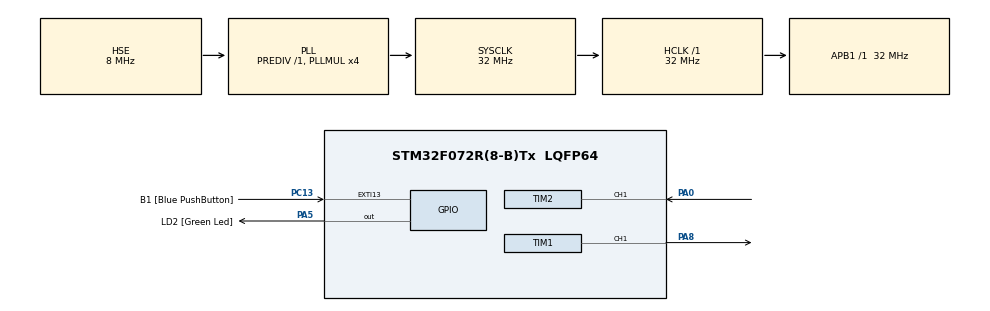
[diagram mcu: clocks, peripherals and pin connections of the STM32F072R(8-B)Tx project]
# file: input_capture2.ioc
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Mcu.Family=STM32F0
Mcu.Name=STM32F072R(8-B)Tx
Mcu.Package=LQFP64
NVIC.TIM2_IRQn=true\:0\:0\:false\:false\:true\:true\:true\:true
PA0.Signal=S_TIM2_CH1_ETR
PA13.GPIO_Label=TMS
PA13.Signal=SYS_SWDIO
PA14.GPIO_Label=TCK
PA14.Signal=SYS_SWCLK
PA2.GPIO_Label=USART_TX
PA2.GPIO_Mode=GPIO_MODE_AF_PP
PA2.GPIO_PuPd=GPIO_NOPULL
PA2.GPIO_Speed=GPIO_SPEED_FREQ_LOW
PA2.Signal=USART2_TX
PA3.GPIO_Label=USART_RX
PA3.GPIO_Mode=GPIO_MODE_AF_PP
PA3.GPIO_PuPd=GPIO_NOPULL
PA3.GPIO_Speed=GPIO_SPEED_FREQ_LOW
PA3.Signal=USART2_RX
PA5.GPIO_Label=LD2 [Green Led]
PA5.GPIO_Mode=GPIO_MODE_OUTPUT_PP
PA5.GPIO_PuPd=GPIO_NOPULL
PA5.GPIO_Speed=GPIO_SPEED_FREQ_LOW
PA5.Signal=GPIO_Output
PA8.Signal=S_TIM1_CH1
PC13.GPIO_Label=B1 [Blue PushButton]
PC13.GPIO_ModeDefaultEXTI=GPIO_MODE_IT_FALLING
PC13.Signal=GPXTI13
PC14-OSC32_IN.Signal=RCC_OSC32_IN
PC15-OSC32_OUT.Signal=RCC_OSC32_OUT
PF0-OSC_IN.Mode=HSE-External-Oscillator
PF0-OSC_IN.Signal=RCC_OSC_IN
PF1-OSC_OUT.Mode=HSE-External-Oscillator
PF1-OSC_OUT.Signal=RCC_OSC_OUT
ProjectManager.HeapSize=0x200
ProjectManager.StackSize=0x400
ProjectManager.TargetToolchain=STM32CubeIDE
RCC.AHBFreq_Value=32000000
RCC.APB1Freq_Value=32000000
RCC.APB1TimFreq_Value=32000000
RCC.FLatency-AdvancedSettings=FLASH_LATENCY_1
RCC.HCLKFreq_Value=32000000
RCC.PLLMUL=RCC_PLL_MUL4
RCC.PLLSourceVirtual=RCC_PLLSOURCE_HSE
RCC.SYSCLKFreq_VALUE=32000000
RCC.SYSCLKSource=RCC_SYSCLKSOURCE_PLLCLK
SH.S_TIM1_CH1.0=TIM1_CH1,PWM Generation1 CH1
SH.S_TIM2_CH1_ETR.0=TIM2_CH1,PWM_Input_1
TIM1.Channel-PWM\ Generation1\ CH1=TIM_CHANNEL_1
TIM1.Period=200-1
TIM1.Prescaler=32-1
TIM1.Pulse-PWM\ Generation1\ CH1=99
TIM2.Prescaler=32-1
VP_TIM1_VS_ClockSourceINT.Mode=Internal
VP_TIM2_VS_ClockSourceINT.Mode=Internal
board=NUCLEO-F072RB

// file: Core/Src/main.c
/* USER CODE BEGIN Header */
/**
  ******************************************************************************
  * @file           : main.c
  * @brief          : Main program body
  ******************************************************************************
  * @attention
  *
  * Copyright (c) 2022 STMicroelectronics.
  * All rights reserved.
  *
  * This software is licensed under terms that can be found in the LICENSE file
  * in the root directory of this software component.
  * If no LICENSE file comes with this software, it is provided AS-IS.
  *
  ******************************************************************************
  */
/* USER CODE END Header */
#include "main.h"

 TIM_HandleTypeDef htim1;
TIM_HandleTypeDef htim2;

void SystemClock_Config(void);
static void MX_GPIO_Init(void);
static void MX_TIM1_Init(void);
static void MX_TIM2_Init(void);

/* USER CODE BEGIN 0 */
uint32_t Icval = 0;
uint32_t freq = 0;
float duty = 0;

void HAL_TIM_IC_CaptureCallback(TIM_HandleTypeDef *htim){
if(htim->Channel == HAL_TIM_ACTIVE_CHANNEL_1)//when channel-1 activated
{

		 Icval = HAL_TIM_ReadCapturedValue(htim,TIM_CHANNEL_1);

		 if(Icval!=0){
			duty = (HAL_TIM_ReadCapturedValue(htim,TIM_CHANNEL_2)*100/Icval);
			freq = 1000000/Icval;
		 }
	 }
}
/* USER CODE END 0 */

int main(void)
{

  /* MCU Configuration--------------------------------------------------------*/

  /* Reset of all peripherals, Initializes the Flash interface and the Systick. */
  HAL_Init();

  /* Configure the system clock */
  SystemClock_Config();

  /* Initialize all configured peripherals */
  MX_GPIO_Init();
  MX_TIM1_Init();
  MX_TIM2_Init();
  /* USER CODE BEGIN 2 */
  HAL_TIM_IC_Start_IT(&htim2,TIM_CHANNEL_1);//direct mode
  HAL_TIM_IC_Start(&htim2,TIM_CHANNEL_2);//indirect mode
  //TIM1->CCR1 = 100;//pwm arrangement to %50
  HAL_TIM_PWM_Start(&htim1,TIM_CHANNEL_1);//starting pwm operation
  /* USER CODE END 2 */

  /* Infinite loop */
  while (1)
  {

    /* USER CODE BEGIN 3 */
	  HAL_Delay(1000);
  }
  /* USER CODE END 3 */
}

void SystemClock_Config(void)
{
  RCC_OscInitTypeDef RCC_OscInitStruct = {0};
  RCC_ClkInitTypeDef RCC_ClkInitStruct = {0};

  /** Initializes the RCC Oscillators according to the specified parameters
  * in the RCC_OscInitTypeDef structure.
  */
  RCC_OscInitStruct.OscillatorType = RCC_OSCILLATORTYPE_HSE;
  RCC_OscInitStruct.HSEState = RCC_HSE_ON;
  RCC_OscInitStruct.PLL.PLLState = RCC_PLL_ON;
  RCC_OscInitStruct.PLL.PLLSource = RCC_PLLSOURCE_HSE;
  RCC_OscInitStruct.PLL.PLLMUL = RCC_PLL_MUL4;
  RCC_OscInitStruct.PLL.PREDIV = RCC_PREDIV_DIV1;
  if (HAL_RCC_OscConfig(&RCC_OscInitStruct) != HAL_OK)
  {
    Error_Handler();
  }

  /** Initializes the CPU, AHB and APB buses clocks
  */
  RCC_ClkInitStruct.ClockType = RCC_CLOCKTYPE_HCLK|RCC_CLOCKTYPE_SYSCLK
                              |RCC_CLOCKTYPE_PCLK1;
  RCC_ClkInitStruct.SYSCLKSource = RCC_SYSCLKSOURCE_PLLCLK;
  RCC_ClkInitStruct.AHBCLKDivider = RCC_SYSCLK_DIV1;
  RCC_ClkInitStruct.APB1CLKDivider = RCC_HCLK_DIV1;

  if (HAL_RCC_ClockConfig(&RCC_ClkInitStruct, FLASH_LATENCY_1) != HAL_OK)
  {
    Error_Handler();
  }
}

static void MX_TIM1_Init(void)
{

  TIM_ClockConfigTypeDef sClockSourceConfig = {0};
  TIM_MasterConfigTypeDef sMasterConfig = {0};
  TIM_OC_InitTypeDef sConfigOC = {0};
  TIM_BreakDeadTimeConfigTypeDef sBreakDeadTimeConfig = {0};

  htim1.Instance = TIM1;
  htim1.Init.Prescaler = 32-1;
  htim1.Init.CounterMode = TIM_COUNTERMODE_UP;
  htim1.Init.Period = 200-1;
  htim1.Init.ClockDivision = TIM_CLOCKDIVISION_DIV1;
  htim1.Init.RepetitionCounter = 0;
  htim1.Init.AutoReloadPreload = TIM_AUTORELOAD_PRELOAD_DISABLE;
  if (HAL_TIM_Base_Init(&htim1) != HAL_OK)
  {
    Error_Handler();
  }
  sClockSourceConfig.ClockSource = TIM_CLOCKSOURCE_INTERNAL;
  if (HAL_TIM_ConfigClockSource(&htim1, &sClockSourceConfig) != HAL_OK)
  {
    Error_Handler();
  }
  if (HAL_TIM_PWM_Init(&htim1) != HAL_OK)
  {
    Error_Handler();
  }
  sMasterConfig.MasterOutputTrigger = TIM_TRGO_RESET;
  sMasterConfig.MasterSlaveMode = TIM_MASTERSLAVEMODE_DISABLE;
  if (HAL_TIMEx_MasterConfigSynchronization(&htim1, &sMasterConfig) != HAL_OK)
  {
    Error_Handler();
  }
  sConfigOC.OCMode = TIM_OCMODE_PWM1;
  sConfigOC.Pulse = 99;
  sConfigOC.OCPolarity = TIM_OCPOLARITY_HIGH;
  sConfigOC.OCNPolarity = TIM_OCNPOLARITY_HIGH;
  sConfigOC.OCFastMode = TIM_OCFAST_DISABLE;
  sConfigOC.OCIdleState = TIM_OCIDLESTATE_RESET;
  sConfigOC.OCNIdleState = TIM_OCNIDLESTATE_RESET;
  if (HAL_TIM_PWM_ConfigChannel(&htim1, &sConfigOC, TIM_CHANNEL_1) != HAL_OK)
  {
    Error_Handler();
  }
  sBreakDeadTimeConfig.OffStateRunMode = TIM_OSSR_DISABLE;
  sBreakDeadTimeConfig.OffStateIDLEMode = TIM_OSSI_DISABLE;
  sBreakDeadTimeConfig.LockLevel = TIM_LOCKLEVEL_OFF;
  sBreakDeadTimeConfig.DeadTime = 0;
  sBreakDeadTimeConfig.BreakState = TIM_BREAK_DISABLE;
  sBreakDeadTimeConfig.BreakPolarity = TIM_BREAKPOLARITY_HIGH;
  sBreakDeadTimeConfig.AutomaticOutput = TIM_AUTOMATICOUTPUT_DISABLE;
  if (HAL_TIMEx_ConfigBreakDeadTime(&htim1, &sBreakDeadTimeConfig) != HAL_OK)
  {
    Error_Handler();
  }
  HAL_TIM_MspPostInit(&htim1);

}

static void MX_TIM2_Init(void)
{

  TIM_ClockConfigTypeDef sClockSourceConfig = {0};
  TIM_SlaveConfigTypeDef sSlaveConfig = {0};
  TIM_IC_InitTypeDef sConfigIC = {0};
  TIM_MasterConfigTypeDef sMasterConfig = {0};

  htim2.Instance = TIM2;
  htim2.Init.Prescaler = 32-1;
  htim2.Init.CounterMode = TIM_COUNTERMODE_UP;
  htim2.Init.Period = 4294967295;
  htim2.Init.ClockDivision = TIM_CLOCKDIVISION_DIV1;
  htim2.Init.AutoReloadPreload = TIM_AUTORELOAD_PRELOAD_DISABLE;
  if (HAL_TIM_Base_Init(&htim2) != HAL_OK)
  {
    Error_Handler();
  }
  sClockSourceConfig.ClockSource = TIM_CLOCKSOURCE_INTERNAL;
  if (HAL_TIM_ConfigClockSource(&htim2, &sClockSourceConfig) != HAL_OK)
  {
    Error_Handler();
  }
  if (HAL_TIM_IC_Init(&htim2) != HAL_OK)
  {
    Error_Handler();
  }
  sSlaveConfig.SlaveMode = TIM_SLAVEMODE_RESET;
  sSlaveConfig.InputTrigger = TIM_TS_TI1FP1;
  sSlaveConfig.TriggerPolarity = TIM_INPUTCHANNELPOLARITY_RISING;
  sSlaveConfig.TriggerPrescaler = TIM_ICPSC_DIV1;
  sSlaveConfig.TriggerFilter = 0;
  if (HAL_TIM_SlaveConfigSynchro(&htim2, &sSlaveConfig) != HAL_OK)
  {
    Error_Handler();
  }
  sConfigIC.ICPolarity = TIM_INPUTCHANNELPOLARITY_RISING;
  sConfigIC.ICSelection = TIM_ICSELECTION_DIRECTTI;
  sConfigIC.ICPrescaler = TIM_ICPSC_DIV1;
  sConfigIC.ICFilter = 0;
  if (HAL_TIM_IC_ConfigChannel(&htim2, &sConfigIC, TIM_CHANNEL_1) != HAL_OK)
  {
    Error_Handler();
  }
  sConfigIC.ICPolarity = TIM_INPUTCHANNELPOLARITY_FALLING;
  sConfigIC.ICSelection = TIM_ICSELECTION_INDIRECTTI;
  if (HAL_TIM_IC_ConfigChannel(&htim2, &sConfigIC, TIM_CHANNEL_2) != HAL_OK)
  {
    Error_Handler();
  }
  sMasterConfig.MasterOutputTrigger = TIM_TRGO_RESET;
  sMasterConfig.MasterSlaveMode = TIM_MASTERSLAVEMODE_DISABLE;
  if (HAL_TIMEx_MasterConfigSynchronization(&htim2, &sMasterConfig) != HAL_OK)
  {
    Error_Handler();
  }

}

static void MX_GPIO_Init(void)
{
  GPIO_InitTypeDef GPIO_InitStruct = {0};

  /* GPIO Ports Clock Enable */
  __HAL_RCC_GPIOC_CLK_ENABLE();
  __HAL_RCC_GPIOF_CLK_ENABLE();
  __HAL_RCC_GPIOA_CLK_ENABLE();

  /*Configure GPIO pin Output Level */
  HAL_GPIO_WritePin(LD2_GPIO_Port, LD2_Pin, GPIO_PIN_RESET);

  /*Configure GPIO pin : B1_Pin */
  GPIO_InitStruct.Pin = B1_Pin;
  GPIO_InitStruct.Mode = GPIO_MODE_IT_FALLING;
  GPIO_InitStruct.Pull = GPIO_NOPULL;
  HAL_GPIO_Init(B1_GPIO_Port, &GPIO_InitStruct);

  /*Configure GPIO pins : USART_TX_Pin USART_RX_Pin */
  GPIO_InitStruct.Pin = USART_TX_Pin|USART_RX_Pin;
  GPIO_InitStruct.Mode = GPIO_MODE_AF_PP;
  GPIO_InitStruct.Pull = GPIO_NOPULL;
  GPIO_InitStruct.Speed = GPIO_SPEED_FREQ_LOW;
  GPIO_InitStruct.Alternate = GPIO_AF1_USART2;
  HAL_GPIO_Init(GPIOA, &GPIO_InitStruct);

  /*Configure GPIO pin : LD2_Pin */
  GPIO_InitStruct.Pin = LD2_Pin;
  GPIO_InitStruct.Mode = GPIO_MODE_OUTPUT_PP;
  GPIO_InitStruct.Pull = GPIO_NOPULL;
  GPIO_InitStruct.Speed = GPIO_SPEED_FREQ_LOW;
  HAL_GPIO_Init(LD2_GPIO_Port, &GPIO_InitStruct);

}

void Error_Handler(void)
{
  __disable_irq();
  while (1)
  {
  }
}
